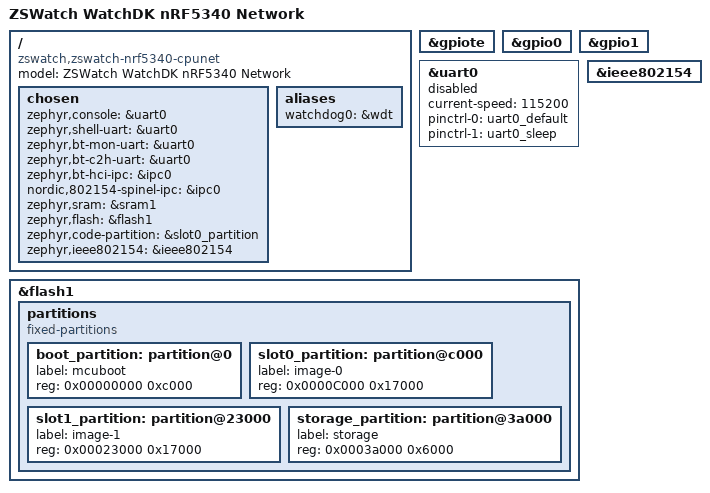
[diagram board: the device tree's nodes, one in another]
/*
 * Copyright (c) 2025 ZSWatch Project
 * SPDX-License-Identifier: Apache-2.0
 */

/dts-v1/;
#include <nordic/nrf5340_cpunet_qkaa.dtsi>
#include "watchdk_nrf5340_cpunet-pinctrl.dtsi"

/ {
    model = "ZSWatch WatchDK nRF5340 Network";
    compatible = "zswatch,zswatch-nrf5340-cpunet";

    chosen {
        zephyr,console = &uart0;
        zephyr,shell-uart = &uart0;
        zephyr,bt-mon-uart = &uart0;
        zephyr,bt-c2h-uart = &uart0;
        zephyr,bt-hci-ipc = &ipc0;
        nordic,802154-spinel-ipc = &ipc0;
        zephyr,sram = &sram1;
        zephyr,flash = &flash1;
        zephyr,code-partition = &slot0_partition;
        zephyr,ieee802154 = &ieee802154;
    };

    /* These aliases are provided for compatibility with samples */
    aliases {
        watchdog0 = &wdt;
    };
};

&gpiote {
    status = "okay";
};

&gpio0 {
    status = "okay";
};

&gpio1 {
    status = "okay";
};

&uart0 {
    status = "disabled";
    current-speed = <115200>;
    pinctrl-0 = <&uart0_default>;
    pinctrl-1 = <&uart0_sleep>;
    pinctrl-names = "default", "sleep";
};

&flash1 {
    partitions {
        compatible = "fixed-partitions";
        #address-cells = <1>;
        #size-cells = <1>;

        boot_partition: partition@0 {
            label = "mcuboot";
            reg = <0x00000000 0xc000>;
        };
        slot0_partition: partition@c000 {
            label = "image-0";
            reg = <0x0000C000 0x17000>;
        };
        slot1_partition: partition@23000 {
            label = "image-1";
            reg = <0x00023000 0x17000>;
        };
        storage_partition: partition@3a000 {
            label = "storage";
            reg = <0x0003a000 0x6000>;
        };
    };
};

&ieee802154 {
    status = "okay";
};

/* Include shared RAM configuration file */
#include "nrf5340_shared_sram_planning_conf.dtsi"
